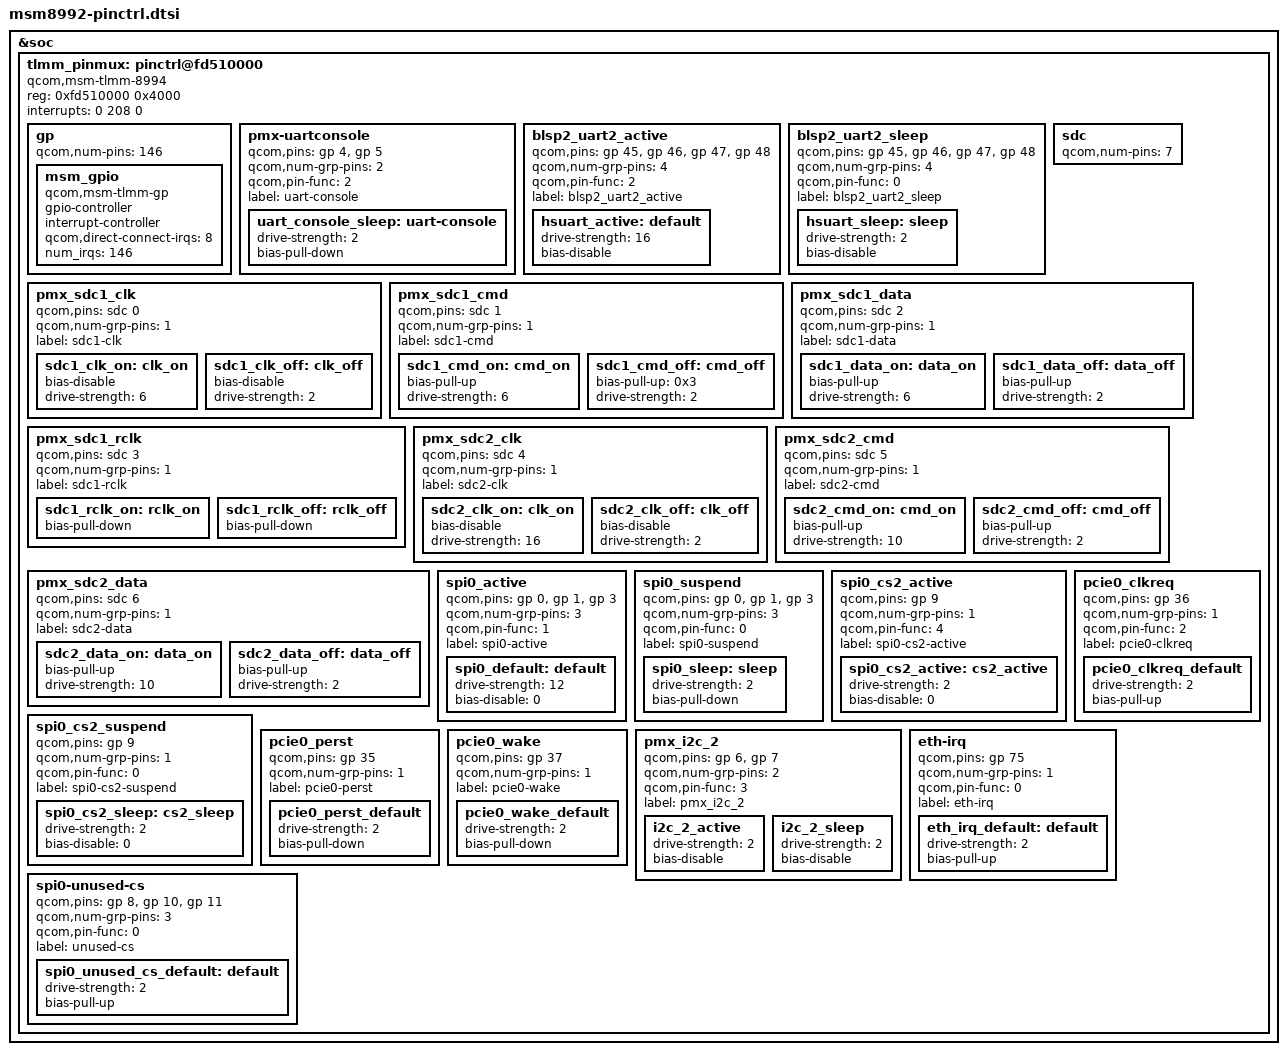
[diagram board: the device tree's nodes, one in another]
/* Copyright (c) 2013-2014, The Linux Foundation. All rights reserved.
 *
 * This program is free software; you can redistribute it and/or modify
 * it under the terms of the GNU General Public License version 2 and
 * only version 2 as published by the Free Software Foundation.
 *
 * This program is distributed in the hope that it will be useful,
 * but WITHOUT ANY WARRANTY; without even the implied warranty of
 * MERCHANTABILITY or FITNESS FOR A PARTICULAR PURPOSE.  See the
 * GNU General Public License for more details.
 */

&soc {
	tlmm_pinmux: pinctrl@fd510000 {
		compatible = "qcom,msm-tlmm-8994", "qcom,msm-tlmm-8974";
		reg = <0xfd510000 0x4000>;
		interrupts = <0 208 0>;

		/*General purpose pins*/
		gp: gp {
			qcom,num-pins = <146>;
			#qcom,pin-cells = <1>;

			msm_gpio: msm_gpio {
				compatible = "qcom,msm-tlmm-gp";
				gpio-controller;
				#gpio-cells = <2>;
				interrupt-controller;
				#interrupt-cells = <2>;
				qcom,direct-connect-irqs = <8>;
				num_irqs = <146>;
			};
		};

		pmx-uartconsole {
			qcom,pins = <&gp 4>, <&gp 5>;
			qcom,num-grp-pins = <2>;
			qcom,pin-func = <2>;
			label = "uart-console";

		uart_console_sleep: uart-console {
				drive-strength = <2>;
				bias-pull-down;
			};
		};

		blsp2_uart2_active {
			qcom,pins = <&gp 45>, <&gp 46>, <&gp 47>, <&gp 48>;
			qcom,num-grp-pins = <4>;
			qcom,pin-func = <2>;
		        label = "blsp2_uart2_active";
			hsuart_active: default {
				drive-strength = <16>;
				bias-disable;
			};
		};

		blsp2_uart2_sleep {
			qcom,pins = <&gp 45>, <&gp 46>, <&gp 47>, <&gp 48>;
			qcom,num-grp-pins = <4>;
			qcom,pin-func = <0>;
		        label = "blsp2_uart2_sleep";
			hsuart_sleep: sleep {
				drive-strength = <2>;
				bias-disable;
			};
		};

		/* SDC pin type */
		sdc: sdc {
			/* 0-3 for sdc1 4-6 for sdc2 */
			qcom,num-pins = <7>;
			/* Order of pins */
			/* SDC1: CLK -> 0, CMD -> 1, DATA -> 2, RCLK -> 3 */
			/* SDC2: CLK -> 4, CMD -> 5, DATA -> 6 */
			#qcom,pin-cells = <1>;
		};

		pmx_sdc1_clk {
			qcom,pins = <&sdc 0>;
			qcom,num-grp-pins = <1>;
			label = "sdc1-clk";
			sdc1_clk_on: clk_on {
				bias-disable; /* NO pull */
				drive-strength = <6>; /* 6 MA */
			};
			sdc1_clk_off: clk_off {
				bias-disable; /* NO pull */
				drive-strength = <2>; /* 2 MA */
			};
		};

		pmx_sdc1_cmd {
			qcom,pins = <&sdc 1>;
			qcom,num-grp-pins = <1>;
			label = "sdc1-cmd";
			sdc1_cmd_on: cmd_on {
				bias-pull-up; /* pull up */
				drive-strength = <6>; /* 6 MA */
			};
			sdc1_cmd_off: cmd_off {
				bias-pull-up = <0x3>; /* pull up */
				drive-strength = <2>; /* 2 MA */
			};
		};

		pmx_sdc1_data {
			qcom,pins = <&sdc 2>;
			qcom,num-grp-pins = <1>;
			label = "sdc1-data";
			sdc1_data_on: data_on {
				bias-pull-up; /* pull up */
				drive-strength = <6>; /* 6 MA */
			};
			sdc1_data_off: data_off {
				bias-pull-up; /* pull up */
				drive-strength = <2>; /* 2 MA */
			};
		};

		pmx_sdc1_rclk {
			qcom,pins = <&sdc 3>;
			qcom,num-grp-pins = <1>;
			label = "sdc1-rclk";
			sdc1_rclk_on: rclk_on {
				bias-pull-down; /* pull down */
			};
			sdc1_rclk_off: rclk_off {
				bias-pull-down; /* pull down */
			};
		};

		pmx_sdc2_clk {
			qcom,pins = <&sdc 4>;
			qcom,num-grp-pins = <1>;
			label = "sdc2-clk";
			sdc2_clk_on: clk_on {
				bias-disable; /* NO pull */
				drive-strength = <16>; /* 16 MA */
			};
			sdc2_clk_off: clk_off {
				bias-disable; /* NO pull */
				drive-strength = <2>; /* 2 MA */
			};
		};

		pmx_sdc2_cmd {
			qcom,pins = <&sdc 5>;
			qcom,num-grp-pins = <1>;
			label = "sdc2-cmd";
			sdc2_cmd_on: cmd_on {
				bias-pull-up; /* pull up */
				drive-strength = <10>; /* 10 MA */
			};
			sdc2_cmd_off: cmd_off {
				bias-pull-up; /* pull up */
				drive-strength = <2>; /* 2 MA */
			};
		};

		pmx_sdc2_data {
			qcom,pins = <&sdc 6>;
			qcom,num-grp-pins = <1>;
			label = "sdc2-data";
			sdc2_data_on: data_on {
				bias-pull-up; /* pull up */
				drive-strength = <10>; /* 10 MA */
			};
			sdc2_data_off: data_off {
				bias-pull-up; /* pull up */
				drive-strength = <2>; /* 2 MA */
			};
		};

		spi0_active {
			/* MOSI, MISO, CLK */
			qcom,pins = <&gp 0>, <&gp 1>, <&gp 3>;
			qcom,num-grp-pins = <3>;
			qcom,pin-func = <1>;
			label = "spi0-active";
			/* active state */
			spi0_default: default {
				drive-strength = <12>; /* 12 MA */
				bias-disable = <0>; /* No PULL */
			};
		};

		spi0_suspend {
			/* MOSI, MISO, CLK */
			qcom,pins = <&gp 0>, <&gp 1>, <&gp 3>;
			qcom,num-grp-pins = <3>;
			qcom,pin-func = <0>;
			label = "spi0-suspend";
			/* suspended state */
			spi0_sleep: sleep {
				drive-strength = <2>; /* 2 MA */
				bias-pull-down; /* pull down */
			};
		};

		spi0_cs2_active {
			/* CS */
			qcom,pins = <&gp 9>;
			qcom,num-grp-pins = <1>;
			qcom,pin-func = <4>;
			label = "spi0-cs2-active";
			spi0_cs2_active: cs2_active {
				drive-strength = <2>;
				bias-disable = <0>;
			};
		};

		spi0_cs2_suspend {
			/* CS */
			qcom,pins = <&gp 9>;
			qcom,num-grp-pins = <1>;
			qcom,pin-func = <0>;
			label = "spi0-cs2-suspend";
			spi0_cs2_sleep: cs2_sleep {
				drive-strength = <2>;
				bias-disable = <0>;
			};
		};

		pcie0_clkreq {
			qcom,pins = <&gp 36>;
			qcom,num-grp-pins = <1>;
			qcom,pin-func = <2>;
			label = "pcie0-clkreq";
			/* default state */
			pcie0_clkreq_default: pcie0_clkreq_default {
				drive-strength = <2>;
				bias-pull-up;
			};
		};

		pcie0_perst {
			qcom,pins = <&gp 35>;
			qcom,num-grp-pins = <1>;
			label = "pcie0-perst";
			/* default state */
			pcie0_perst_default: pcie0_perst_default {
				drive-strength = <2>;
				bias-pull-down;
			};
		};

		pcie0_wake {
			qcom,pins = <&gp 37>;
			qcom,num-grp-pins = <1>;
			label = "pcie0-wake";
			/* default state */
			pcie0_wake_default: pcie0_wake_default {
				drive-strength = <2>;
				bias-pull-down;
			};
		};

		pmx_i2c_2 {
			qcom,pins = <&gp 6>, <&gp 7>; /* SDA, SCL */
			qcom,num-grp-pins = <2>;
			qcom,pin-func = <3>;
			label = "pmx_i2c_2";

			i2c_2_active: i2c_2_active {
				drive-strength = <2>;
				bias-disable;
			};

			i2c_2_sleep: i2c_2_sleep {
				drive-strength = <2>;
				bias-disable;
			};
		};

		eth-irq {
			qcom,pins = <&gp 75>;
			qcom,num-grp-pins = <1>;
			qcom,pin-func = <0>;
			label = "eth-irq";
			eth_irq_default: default {
				drive-strength = <2>;
				bias-pull-up;
			};
		};

		spi0-unused-cs {
			qcom,pins = <&gp 8>, <&gp 10>, <&gp 11>;
			qcom,num-grp-pins = <3>;
			qcom,pin-func = <0>;
			label = "unused-cs";
			spi0_unused_cs_default: default {
				drive-strength = <2>;
				bias-pull-up;
			};
		};
	};
};
